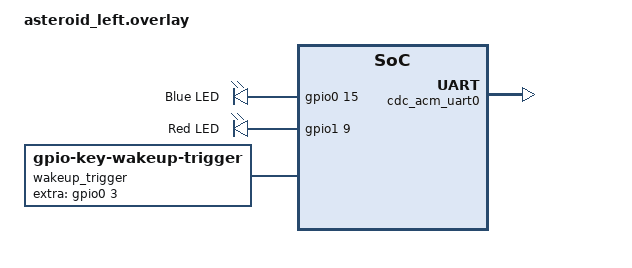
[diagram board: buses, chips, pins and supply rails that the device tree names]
#include "asteroid.dtsi"

// Override the transform for standalone left keyboard
&default_transform {
    col-offset = <0>;
};

// Add CDC-ACM console for ZMK Studio USB communication
/ {
    chosen {
        zephyr,console = &cdc_acm_uart0;
        zmk,led = &red_led;  // Use red LED for charging completion status
    };

    // LED configuration for Pro Micro nRF52840 clone
    leds {
        compatible = "gpio-leds";
        blue_led: led_0 {
            gpios = <&gpio0 15 GPIO_ACTIVE_HIGH>;
            label = "Blue LED";
        };
        red_led: led_1 {
            gpios = <&gpio1 9 GPIO_ACTIVE_HIGH>;
            label = "Red LED";
        };
    };

    // Soft-off wake-up configuration
    soft_off_wakers {
        compatible = "zmk,soft-off-wakeup-sources";
        wakeup-sources = <&wakeup_trigger>;
    };

    wakeup_trigger: wakeup_trigger {
        compatible = "zmk,gpio-key-wakeup-trigger";
        wakeup-source;
        extra-gpios = <&gpio0 3 (GPIO_ACTIVE_HIGH | GPIO_PULL_DOWN)>;
    };
};

&zephyr_udc0 {
    cdc_acm_uart0: cdc_acm_uart0 {
        compatible = "zephyr,cdc-acm-uart";
        label = "CDC_ACM_0";
    };
};

&kscan0 {
    row-gpios
        = <&gpio0 6 (GPIO_ACTIVE_HIGH | GPIO_PULL_DOWN)>    // P0.06 - Row 1
        , <&gpio0 8 (GPIO_ACTIVE_HIGH | GPIO_PULL_DOWN)>    // P0.08 - Row 2
        , <&gpio0 20 (GPIO_ACTIVE_HIGH | GPIO_PULL_DOWN)>   // P0.20 - Row 3
        , <&gpio0 22 (GPIO_ACTIVE_HIGH | GPIO_PULL_DOWN)>   // P0.22 - Row 4
        , <&gpio0 24 (GPIO_ACTIVE_HIGH | GPIO_PULL_DOWN)>   // P0.24 - Row 5
        // Row 6 (P0.11) removed - not physically present
        ;
    col-gpios
        = <&gpio1 15 GPIO_ACTIVE_HIGH>  // P1.15 (115) - Col 1
        , <&gpio1 0 GPIO_ACTIVE_HIGH>   // P1.00 (100) - Col 2
        , <&gpio1 4 GPIO_ACTIVE_HIGH>   // P1.04 (104) - Col 3
        , <&gpio1 6 GPIO_ACTIVE_HIGH>   // P1.06 (106) - Col 4
        , <&gpio1 13 GPIO_ACTIVE_HIGH>  // P1.13 (113) - Col 5
        , <&gpio1 11 GPIO_ACTIVE_HIGH>  // P1.11 (111) - Col 6
        ;
};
